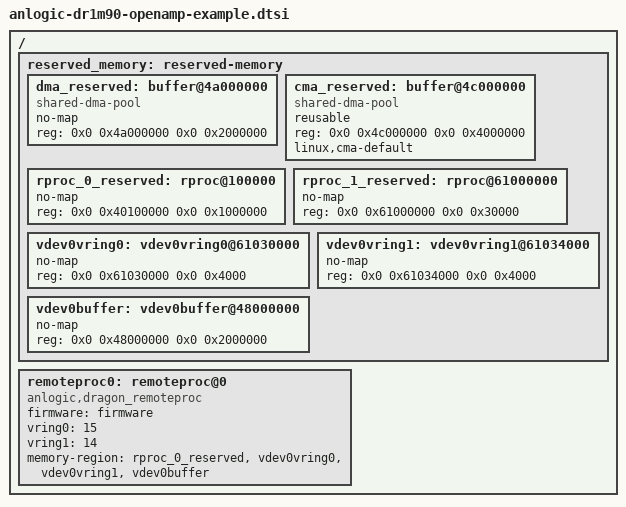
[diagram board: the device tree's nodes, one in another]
/*
 * Example device tree nodes for openamp demo, APU0 linux + APU1 baremetal mode
 */

/ {
    reserved_memory: reserved-memory {
	#address-cells = <2>;
	#size-cells = <2>;
	ranges;

	dma_reserved: buffer@4a000000 {
		 compatible = "shared-dma-pool";
		 no-map;
		 reg = <0x0 0x4a000000 0x0 0x2000000>;

	};

	cma_reserved: buffer@4c000000 {
		 compatible = "shared-dma-pool";
		 reusable;
		 reg = <0x0 0x4c000000 0x0 0x4000000>;
		 linux,cma-default;

	};

	/* Reserved memory for loading remote firmware */
	rproc_0_reserved: rproc@100000 {
		no-map;
		/* 16MB in DDR */
		reg = <0x0 0x40100000 0x0 0x1000000>;

	};
		
	/* Reserved memory for loading remote firmware */
	rproc_1_reserved: rproc@61000000 {
		no-map;
		/* 192KB in OCM */
		reg = <0x0 0x61000000 0x0 0x30000>;

	};
		
	/* Reserved memory for vring0 */
	vdev0vring0: vdev0vring0@61030000 {
		no-map;
		/* 16KB in OCM */
		reg = <0x0 0x61030000 0x0 0x4000>;

	};

	/* Reserved memory for vring1 */
	vdev0vring1: vdev0vring1@61034000 {
		no-map;
		/* 16KB in OCM */
		reg = <0x0 0x61034000 0x0 0x4000>;

	};

	/* Reserved memory for shared buffer */
	vdev0buffer: vdev0buffer@48000000 {
		no-map;
		/* 32MB in DDR */
		reg = <0x0 0x48000000 0x0 0x2000000>;

	};
    };

    remoteproc0: remoteproc@0 {
	compatible = "anlogic,dragon_remoteproc";
	firmware = "firmware";
	vring0 = <15>;
	vring1 = <14>;
	memory-region = <&rproc_0_reserved>, <&vdev0vring0>, <&vdev0vring1>, <&vdev0buffer>;
    };
};


